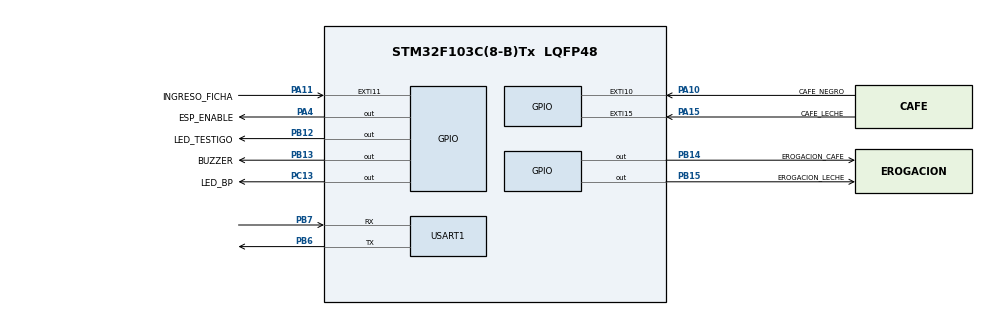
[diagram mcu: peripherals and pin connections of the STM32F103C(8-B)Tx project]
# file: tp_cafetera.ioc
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Mcu.Family=STM32F1
Mcu.Name=STM32F103C(8-B)Tx
Mcu.Package=LQFP48
NVIC.EXTI15_10_IRQn=true\:0\:0\:false\:false\:true\:true\:true\:true
NVIC.PriorityGroup=NVIC_PRIORITYGROUP_4
NVIC.USART1_IRQn=true\:0\:0\:false\:false\:true\:true\:true\:true
PA10.GPIO_Label=CAFE_NEGRO
PA10.GPIO_PuPd=GPIO_PULLDOWN
PA10.Signal=GPXTI10
PA11.GPIO_Label=INGRESO_FICHA
PA11.GPIO_PuPd=GPIO_PULLDOWN
PA11.Signal=GPXTI11
PA13.Mode=Serial_Wire
PA13.Signal=SYS_JTMS-SWDIO
PA14.Mode=Serial_Wire
PA14.Signal=SYS_JTCK-SWCLK
PA15.GPIO_Label=CAFE_LECHE
PA15.GPIO_PuPd=GPIO_PULLDOWN
PA15.Signal=GPXTI15
PA4.GPIO_Label=ESP_ENABLE
PA4.Signal=GPIO_Output
PB12.GPIO_Label=LED_TESTIGO
PB12.Signal=GPIO_Output
PB13.GPIO_Label=BUZZER
PB13.Signal=GPIO_Output
PB14.GPIO_Label=EROGACION_CAFE
PB14.Signal=GPIO_Output
PB15.GPIO_Label=EROGACION_LECHE
PB15.Signal=GPIO_Output
PB6.Mode=Asynchronous
PB6.Signal=USART1_TX
PB7.Mode=Asynchronous
PB7.Signal=USART1_RX
PC13-TAMPER-RTC.GPIO_Label=LED_BP
PC13-TAMPER-RTC.Signal=GPIO_Output
PC14-OSC32_IN.Mode=LSE-External-Oscillator
PC14-OSC32_IN.Signal=RCC_OSC32_IN
PC15-OSC32_OUT.Mode=LSE-External-Oscillator
PC15-OSC32_OUT.Signal=RCC_OSC32_OUT
PD0-OSC_IN.Mode=HSE-External-Oscillator
PD0-OSC_IN.Signal=RCC_OSC_IN
PD1-OSC_OUT.Mode=HSE-External-Oscillator
PD1-OSC_OUT.Signal=RCC_OSC_OUT
ProjectManager.HeapSize=0x200
ProjectManager.StackSize=0x400
ProjectManager.TargetToolchain=STM32CubeIDE
RCC.APB1Freq_Value=8000000
RCC.APB2Freq_Value=8000000
USART1.VirtualMode=VM_ASYNC
board=custom

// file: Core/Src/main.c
/* USER CODE BEGIN Header */
/**
 ******************************************************************************
 * @file           : main.c
 * @brief          : Main program body
 ******************************************************************************
 * @attention
 *
 * Copyright (c) 2025 STMicroelectronics.
 * All rights reserved.
 *
 * This software is licensed under terms that can be found in the LICENSE file
 * in the root directory of this software component.
 * If no LICENSE file comes with this software, it is provided AS-IS.
 *
 ******************************************************************************
 */
/* USER CODE END Header */
#include "main.h"

/* USER CODE BEGIN Includes */
#include "cafetera.h"
#include "user_gpio.h"
#include "esp8266.h"
/* USER CODE END Includes */

UART_HandleTypeDef huart1;

void SystemClock_Config(void);
static void MX_GPIO_Init(void);
static void MX_USART1_UART_Init(void);

/* USER CODE BEGIN 0 */

void HAL_IncTick(void)
{
	uwTick += uwTickFreq;
	cafetera_tick();
	esp8266_tick();
}

/* USER CODE END 0 */

int main(void)
{

  /* MCU Configuration--------------------------------------------------------*/

  /* Reset of all peripherals, Initializes the Flash interface and the Systick. */
  HAL_Init();

  /* Configure the system clock */
  SystemClock_Config();

  /* Initialize all configured peripherals */
  MX_GPIO_Init();
  MX_USART1_UART_Init();
  /* USER CODE BEGIN 2 */
	user_gpio_init();
	esp8266_init();
	cafetera_init();

  /* USER CODE END 2 */

  /* Infinite loop */
  /* USER CODE BEGIN WHILE */
	while (1)
	{
		esp8266_loop();
		cafetera_runCycle();
		__WFI();
    /* USER CODE END WHILE */

	}
}

void SystemClock_Config(void)
{
  RCC_OscInitTypeDef RCC_OscInitStruct = {0};
  RCC_ClkInitTypeDef RCC_ClkInitStruct = {0};

  /** Initializes the RCC Oscillators according to the specified parameters
  * in the RCC_OscInitTypeDef structure.
  */
  RCC_OscInitStruct.OscillatorType = RCC_OSCILLATORTYPE_HSI;
  RCC_OscInitStruct.HSIState = RCC_HSI_ON;
  RCC_OscInitStruct.HSICalibrationValue = RCC_HSICALIBRATION_DEFAULT;
  RCC_OscInitStruct.PLL.PLLState = RCC_PLL_NONE;
  if (HAL_RCC_OscConfig(&RCC_OscInitStruct) != HAL_OK)
  {
    Error_Handler();
  }

  /** Initializes the CPU, AHB and APB buses clocks
  */
  RCC_ClkInitStruct.ClockType = RCC_CLOCKTYPE_HCLK|RCC_CLOCKTYPE_SYSCLK
                              |RCC_CLOCKTYPE_PCLK1|RCC_CLOCKTYPE_PCLK2;
  RCC_ClkInitStruct.SYSCLKSource = RCC_SYSCLKSOURCE_HSI;
  RCC_ClkInitStruct.AHBCLKDivider = RCC_SYSCLK_DIV1;
  RCC_ClkInitStruct.APB1CLKDivider = RCC_HCLK_DIV1;
  RCC_ClkInitStruct.APB2CLKDivider = RCC_HCLK_DIV1;

  if (HAL_RCC_ClockConfig(&RCC_ClkInitStruct, FLASH_LATENCY_0) != HAL_OK)
  {
    Error_Handler();
  }
}

static void MX_USART1_UART_Init(void)
{

  huart1.Instance = USART1;
  huart1.Init.BaudRate = 115200;
  huart1.Init.WordLength = UART_WORDLENGTH_8B;
  huart1.Init.StopBits = UART_STOPBITS_1;
  huart1.Init.Parity = UART_PARITY_NONE;
  huart1.Init.Mode = UART_MODE_TX_RX;
  huart1.Init.HwFlowCtl = UART_HWCONTROL_NONE;
  huart1.Init.OverSampling = UART_OVERSAMPLING_16;
  if (HAL_UART_Init(&huart1) != HAL_OK)
  {
    Error_Handler();
  }

}

static void MX_GPIO_Init(void)
{
  GPIO_InitTypeDef GPIO_InitStruct = {0};

  /* GPIO Ports Clock Enable */
  __HAL_RCC_GPIOC_CLK_ENABLE();
  __HAL_RCC_GPIOD_CLK_ENABLE();
  __HAL_RCC_GPIOA_CLK_ENABLE();
  __HAL_RCC_GPIOB_CLK_ENABLE();

  /*Configure GPIO pin Output Level */
  HAL_GPIO_WritePin(LED_BP_GPIO_Port, LED_BP_Pin, GPIO_PIN_RESET);

  /*Configure GPIO pin Output Level */
  HAL_GPIO_WritePin(ESP_ENABLE_GPIO_Port, ESP_ENABLE_Pin, GPIO_PIN_RESET);

  /*Configure GPIO pin Output Level */
  HAL_GPIO_WritePin(GPIOB, LED_TESTIGO_Pin|BUZZER_Pin|EROGACION_CAFE_Pin|EROGACION_LECHE_Pin, GPIO_PIN_RESET);

  /*Configure GPIO pin : LED_BP_Pin */
  GPIO_InitStruct.Pin = LED_BP_Pin;
  GPIO_InitStruct.Mode = GPIO_MODE_OUTPUT_PP;
  GPIO_InitStruct.Pull = GPIO_NOPULL;
  GPIO_InitStruct.Speed = GPIO_SPEED_FREQ_LOW;
  HAL_GPIO_Init(LED_BP_GPIO_Port, &GPIO_InitStruct);

  /*Configure GPIO pin : ESP_ENABLE_Pin */
  GPIO_InitStruct.Pin = ESP_ENABLE_Pin;
  GPIO_InitStruct.Mode = GPIO_MODE_OUTPUT_PP;
  GPIO_InitStruct.Pull = GPIO_NOPULL;
  GPIO_InitStruct.Speed = GPIO_SPEED_FREQ_LOW;
  HAL_GPIO_Init(ESP_ENABLE_GPIO_Port, &GPIO_InitStruct);

  /*Configure GPIO pins : LED_TESTIGO_Pin BUZZER_Pin EROGACION_CAFE_Pin EROGACION_LECHE_Pin */
  GPIO_InitStruct.Pin = LED_TESTIGO_Pin|BUZZER_Pin|EROGACION_CAFE_Pin|EROGACION_LECHE_Pin;
  GPIO_InitStruct.Mode = GPIO_MODE_OUTPUT_PP;
  GPIO_InitStruct.Pull = GPIO_NOPULL;
  GPIO_InitStruct.Speed = GPIO_SPEED_FREQ_LOW;
  HAL_GPIO_Init(GPIOB, &GPIO_InitStruct);

  /*Configure GPIO pins : CAFE_NEGRO_Pin INGRESO_FICHA_Pin CAFE_LECHE_Pin */
  GPIO_InitStruct.Pin = CAFE_NEGRO_Pin|INGRESO_FICHA_Pin|CAFE_LECHE_Pin;
  GPIO_InitStruct.Mode = GPIO_MODE_IT_RISING;
  GPIO_InitStruct.Pull = GPIO_PULLDOWN;
  HAL_GPIO_Init(GPIOA, &GPIO_InitStruct);

  /* EXTI interrupt init*/
  HAL_NVIC_SetPriority(EXTI15_10_IRQn, 0, 0);
  HAL_NVIC_EnableIRQ(EXTI15_10_IRQn);

}

void Error_Handler(void)
{
	__disable_irq();
	while (1)
	{
	}
}
